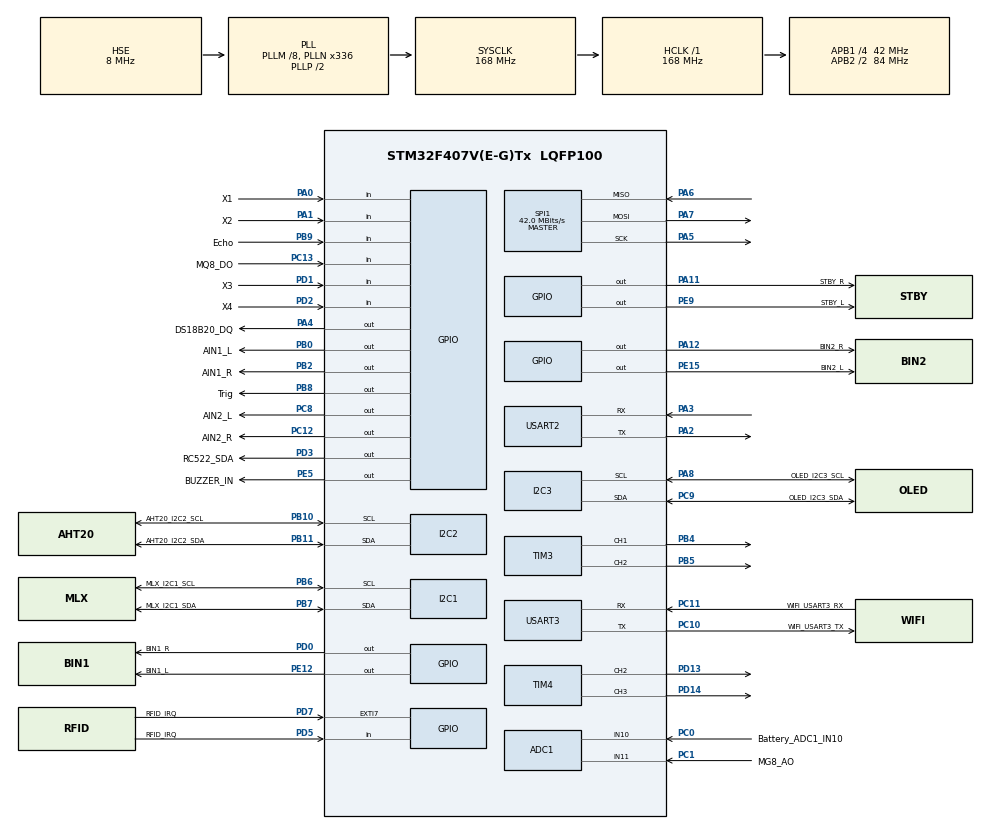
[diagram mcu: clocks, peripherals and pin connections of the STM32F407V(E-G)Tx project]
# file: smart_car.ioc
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ADC1.Channel-0\#ChannelRegularConversion=ADC_CHANNEL_10
ADC1.NbrOfConversionFlag=1
ADC1.Rank-0\#ChannelRegularConversion=1
ADC1.SamplingTime-0\#ChannelRegularConversion=ADC_SAMPLETIME_3CYCLES
ADC1.master=1
FREERTOS.Mutexes01=I2CMutex,Dynamic,NULL,Available
FREERTOS.Queues01=LEDFlash,16,uint32_t,0,Dynamic,NULL,NULL;Distance,16,float,0,Dynamic,NULL,NULL;Track,16,uint8_t,0,Dynamic,NULL,NULL;DriverPWM,16,uint32_t,0,Dynamic,NULL,NULL;MotorAction,16,12,1,Dynamic,NULL,NULL
FREERTOS.Tasks01=LedTask,8,256,StartLedTask,As weak,NULL,Dynamic,NULL,NULL;UartTask,8,256,StartUartTask,As external,NULL,Dynamic,NULL,NULL;OledTask,8,256,StartOledTask,As external,NULL,Dynamic,NULL,NULL;HCSR04Task,48,256,StartHCSR04Task,As external,NULL,Dynamic,NULL,NULL;SensorTask,17,256,StartSensorTask,As external,NULL,Dynamic,NULL,NULL;DriverTask,32,256,StartDriverTask,As external,NULL,Dynamic,NULL,NULL;CtrlTask,24,512,StartCtrlTask,As external,NULL,Dynamic,NULL,NULL;myRfidTask,8,256,StartRfidTask,As external,NULL,Dynamic,NULL,NULL;WifiTask,8,512,StartWifiTask,As external,NULL,Dynamic,NULL,NULL;AITask,8,512,StartAITask,As external,NULL,Dynamic,NULL,NULL
FREERTOS.configCHECK_FOR_STACK_OVERFLOW=2
FREERTOS.configTOTAL_HEAP_SIZE=24576
I2C3.I2C_Mode=I2C_Fast
Mcu.Family=STM32F4
Mcu.Name=STM32F407V(E-G)Tx
Mcu.Package=LQFP100
NVIC.PriorityGroup=NVIC_PRIORITYGROUP_4
NVIC.TIM1_CC_IRQn=true\:5\:0\:false\:false\:true\:true\:true\:true\:true
NVIC.TIM3_IRQn=true\:5\:0\:false\:false\:true\:false\:false\:true\:true
NVIC.TimeBase=TIM3_IRQn
NVIC.TimeBaseIP=TIM3
PA0-WKUP.GPIO_Label=X1
PA0-WKUP.GPIO_PuPd=GPIO_PULLUP
PA0-WKUP.Signal=GPIO_Input
PA1.GPIO_Label=X2
PA1.GPIO_PuPd=GPIO_PULLUP
PA1.Signal=GPIO_Input
PA11.GPIO_Label=STBY_R
PA11.PinState=GPIO_PIN_SET
PA11.Signal=GPIO_Output
PA12.GPIO_Label=BIN2_R
PA12.Signal=GPIO_Output
PA13.Mode=Serial_Wire
PA13.Signal=SYS_JTMS-SWDIO
PA14.Mode=Serial_Wire
PA14.Signal=SYS_JTCK-SWCLK
PA2.Mode=Asynchronous
PA2.Signal=USART2_TX
PA3.Mode=Asynchronous
PA3.Signal=USART2_RX
PA4.GPIO_Label=DS18B20_DQ
PA4.GPIO_ModeDefaultOutputPP=GPIO_MODE_OUTPUT_OD
PA4.GPIO_PuPd=GPIO_NOPULL
PA4.Signal=GPIO_Output
PA5.Mode=Full_Duplex_Master
PA5.Signal=SPI1_SCK
PA6.Mode=Full_Duplex_Master
PA6.Signal=SPI1_MISO
PA7.Mode=Full_Duplex_Master
PA7.Signal=SPI1_MOSI
PA8.GPIO_Label=OLED_I2C3_SCL
PA8.Mode=I2C
PA8.Signal=I2C3_SCL
PB0.GPIO_Label=AIN1_L
PB0.Signal=GPIO_Output
PB10.GPIO_Label=AHT20_I2C2_SCL
PB10.Mode=I2C
PB10.Signal=I2C2_SCL
PB11.GPIO_Label=AHT20_I2C2_SDA
PB11.Mode=I2C
PB11.Signal=I2C2_SDA
PB2.GPIO_Label=AIN1_R
PB2.Signal=GPIO_Output
PB4.Signal=S_TIM3_CH1
PB5.Signal=S_TIM3_CH2
PB6.GPIO_Label=MLX_I2C1_SCL
PB6.Mode=I2C
PB6.Signal=I2C1_SCL
PB7.GPIO_Label=MLX_I2C1_SDA
PB7.Mode=I2C
PB7.Signal=I2C1_SDA
PB8.GPIO_Label=Trig
PB8.Signal=GPIO_Output
PB9.GPIO_Label=Echo
PB9.Signal=GPIO_Input
PC0.GPIO_Label=Battery_ADC1_IN10
PC0.Signal=ADCx_IN10
PC1.GPIO_Label=MG8_AO
PC1.Signal=ADCx_IN11
PC10.GPIO_Label=WiFi_USART3_TX
PC10.Mode=Asynchronous
PC10.Signal=USART3_TX
PC11.GPIO_Label=WiFi_USART3_RX
PC11.Mode=Asynchronous
PC11.Signal=USART3_RX
PC12.GPIO_Label=AIN2_R
PC12.Signal=GPIO_Output
PC13-ANTI_TAMP.GPIO_Label=MQ8_DO
PC13-ANTI_TAMP.Signal=GPIO_Input
PC8.GPIO_Label=AIN2_L
PC8.Signal=GPIO_Output
PC9.GPIO_Label=OLED_I2C3_SDA
PC9.Mode=I2C
PC9.Signal=I2C3_SDA
PD0.GPIO_Label=BIN1_R
PD0.Signal=GPIO_Output
PD1.GPIO_Label=X3
PD1.GPIO_PuPd=GPIO_PULLUP
PD1.Signal=GPIO_Input
PD13.Signal=S_TIM4_CH2
PD14.Signal=S_TIM4_CH3
PD2.GPIO_Label=X4
PD2.GPIO_PuPd=GPIO_PULLUP
PD2.Signal=GPIO_Input
PD3.GPIO_Label=RC522_SDA
PD3.PinState=GPIO_PIN_SET
PD3.Signal=GPIO_Output
PD5.GPIO_Label=RFID_IRQ
PD5.Signal=GPIO_Input
PD7.GPIO_Label=RFID_IRQ 
PD7.Signal=GPXTI7
PE12.GPIO_Label=BIN1_L
PE12.Signal=GPIO_Output
PE15.GPIO_Label=BIN2_L
PE15.Signal=GPIO_Output
PE5.GPIO_Label=BUZZER_IN
PE5.PinState=GPIO_PIN_SET
PE5.Signal=GPIO_Output
PE9.GPIO_Label=STBY_L
PE9.PinState=GPIO_PIN_SET
PE9.Signal=GPIO_Output
PH0-OSC_IN.Mode=HSE-External-Oscillator
PH0-OSC_IN.Signal=RCC_OSC_IN
PH1-OSC_OUT.Mode=HSE-External-Oscillator
PH1-OSC_OUT.Signal=RCC_OSC_OUT
ProjectManager.HeapSize=0x200
ProjectManager.StackSize=0x400
ProjectManager.TargetToolchain=CMake
RCC.48MHZClocksFreq_Value=84000000
RCC.AHBFreq_Value=168000000
RCC.APB1CLKDivider=RCC_HCLK_DIV4
RCC.APB1Freq_Value=42000000
RCC.APB1TimFreq_Value=84000000
RCC.APB2CLKDivider=RCC_HCLK_DIV2
RCC.APB2Freq_Value=84000000
RCC.APB2TimFreq_Value=168000000
RCC.CortexFreq_Value=168000000
RCC.HCLKFreq_Value=168000000
RCC.HSE_VALUE=8000000
RCC.HSI_VALUE=16000000
RCC.LSE_VALUE=32768
RCC.PLLM=8
RCC.PLLN=336
RCC.PLLSourceVirtual=RCC_PLLSOURCE_HSE
RCC.SYSCLKFreq_VALUE=168000000
RCC.SYSCLKSource=RCC_SYSCLKSOURCE_PLLCLK
RCC.VCOOutputFreq_Value=336000000
SH.ADCx_IN10.0=ADC1_IN10,IN10
SH.ADCx_IN11.0=ADC1_IN11,IN11
SH.S_TIM3_CH1.0=TIM3_CH1,PWM Generation1 CH1
SH.S_TIM3_CH2.0=TIM3_CH2,PWM Generation2 CH2
SH.S_TIM4_CH2.0=TIM4_CH2,PWM Generation2 CH2
SH.S_TIM4_CH3.0=TIM4_CH3,PWM Generation3 CH3
SPI1.BaudRatePrescaler=SPI_BAUDRATEPRESCALER_2
SPI1.CalculateBaudRate=42.0 MBits/s
SPI1.Direction=SPI_DIRECTION_2LINES
SPI1.Mode=SPI_MODE_MASTER
SPI1.VirtualType=VM_MASTER
TIM1.Prescaler=167
TIM3.Channel-PWM\ Generation1\ CH1=TIM_CHANNEL_1
TIM3.Channel-PWM\ Generation2\ CH2=TIM_CHANNEL_2
TIM4.Channel-PWM\ Generation2\ CH2=TIM_CHANNEL_2
TIM4.Channel-PWM\ Generation3\ CH3=TIM_CHANNEL_3
USART2.VirtualMode=VM_ASYNC
USART3.VirtualMode=VM_ASYNC
VP_FREERTOS_VS_CMSIS_V2.Mode=CMSIS_V2
VP_SYS_VS_tim8.Mode=TIM8
VP_TIM1_VS_ClockSourceINT.Mode=Internal
board=custom

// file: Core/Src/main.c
/* USER CODE BEGIN Header */
/**
  ******************************************************************************
  * @file           : main.c
  * @brief          : Main program body
  ******************************************************************************
  * @attention
  *
  * Copyright (c) 2026 STMicroelectronics.
  * All rights reserved.
  *
  * This software is licensed under terms that can be found in the LICENSE file
  * in the root directory of this software component.
  * If no LICENSE file comes with this software, it is provided AS-IS.
  *
  ******************************************************************************
  */
/* USER CODE END Header */
#include "main.h"
#include "cmsis_os.h"
#include "adc.h"
#include "i2c.h"
#include "spi.h"
#include "tim.h"
#include "usart.h"
#include "gpio.h"

/* USER CODE BEGIN Includes */
#include "SelfTest.h"

/* USER CODE END Includes */

void SystemClock_Config(void);
void MX_FREERTOS_Init(void);

int main(void)
{

  /* MCU Configuration--------------------------------------------------------*/

  /* Reset of all peripherals, Initializes the Flash interface and the Systick. */
  HAL_Init();

  /* Configure the system clock */
  SystemClock_Config();

  /* Initialize all configured peripherals */
  MX_GPIO_Init();
  MX_I2C1_Init();
  MX_I2C2_Init();
  MX_I2C3_Init();
  MX_TIM4_Init();
  MX_USART2_UART_Init();
  MX_USART3_UART_Init();
  MX_ADC1_Init();
  MX_TIM1_Init();
  MX_SPI1_Init();
  MX_TIM3_Init();
  /* USER CODE BEGIN 2 */
  HAL_Delay(10U);
  SelfTest_Run();
  /* USER CODE END 2 */

  /* Init scheduler */
  osKernelInitialize();  /* Call init function for freertos objects (in cmsis_os2.c) */
  MX_FREERTOS_Init();

  /* Start scheduler */
  osKernelStart();

  /* We should never get here as control is now taken by the scheduler */

  /* Infinite loop */
  while (1)
  {

  }
}

void SystemClock_Config(void)
{
  RCC_OscInitTypeDef RCC_OscInitStruct = {0};
  RCC_ClkInitTypeDef RCC_ClkInitStruct = {0};

  /** Configure the main internal regulator output voltage
  */
  __HAL_RCC_PWR_CLK_ENABLE();
  __HAL_PWR_VOLTAGESCALING_CONFIG(PWR_REGULATOR_VOLTAGE_SCALE1);

  /** Initializes the RCC Oscillators according to the specified parameters
  * in the RCC_OscInitTypeDef structure.
  */
  RCC_OscInitStruct.OscillatorType = RCC_OSCILLATORTYPE_HSE;
  RCC_OscInitStruct.HSEState = RCC_HSE_ON;
  RCC_OscInitStruct.PLL.PLLState = RCC_PLL_ON;
  RCC_OscInitStruct.PLL.PLLSource = RCC_PLLSOURCE_HSE;
  RCC_OscInitStruct.PLL.PLLM = 8;
  RCC_OscInitStruct.PLL.PLLN = 336;
  RCC_OscInitStruct.PLL.PLLP = RCC_PLLP_DIV2;
  RCC_OscInitStruct.PLL.PLLQ = 4;
  if (HAL_RCC_OscConfig(&RCC_OscInitStruct) != HAL_OK)
  {
    Error_Handler();
  }

  /** Initializes the CPU, AHB and APB buses clocks
  */
  RCC_ClkInitStruct.ClockType = RCC_CLOCKTYPE_HCLK|RCC_CLOCKTYPE_SYSCLK
                              |RCC_CLOCKTYPE_PCLK1|RCC_CLOCKTYPE_PCLK2;
  RCC_ClkInitStruct.SYSCLKSource = RCC_SYSCLKSOURCE_PLLCLK;
  RCC_ClkInitStruct.AHBCLKDivider = RCC_SYSCLK_DIV1;
  RCC_ClkInitStruct.APB1CLKDivider = RCC_HCLK_DIV4;
  RCC_ClkInitStruct.APB2CLKDivider = RCC_HCLK_DIV2;

  if (HAL_RCC_ClockConfig(&RCC_ClkInitStruct, FLASH_LATENCY_5) != HAL_OK)
  {
    Error_Handler();
  }
}

void HAL_TIM_PeriodElapsedCallback(TIM_HandleTypeDef *htim)
{
  if (htim->Instance == TIM8)
  {
    HAL_IncTick();
  }
}

void Error_Handler(void)
{
  __disable_irq();
  while (1)
  {
  }
}

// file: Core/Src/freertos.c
/* USER CODE BEGIN Header */
/**
  ******************************************************************************
  * File Name          : freertos.c
  * Description        : Code for freertos applications
  ******************************************************************************
  * @attention
  *
  * Copyright (c) 2026 STMicroelectronics.
  * All rights reserved.
  *
  * This software is licensed under terms that can be found in the LICENSE file
  * in the root directory of this software component.
  * If no LICENSE file comes with this software, it is provided AS-IS.
  *
  ******************************************************************************
  */
/* USER CODE END Header */

#include "FreeRTOS.h"
#include "task.h"
#include "main.h"
#include "cmsis_os.h"

/* USER CODE BEGIN Includes */
#include "Ctrl.h"
#include "runtime_diag.h"

/* USER CODE END Includes */

/* USER CODE BEGIN Variables */
volatile uint32_t task_run_count[10] = {0};

/* USER CODE END Variables */
/* Definitions for LedTask */
osThreadId_t LedTaskHandle;
const osThreadAttr_t LedTask_attributes = {
  .name = "LedTask",
  .stack_size = 256 * 4,
  .priority = (osPriority_t) osPriorityLow,
};
/* Definitions for UartTask */
osThreadId_t UartTaskHandle;
const osThreadAttr_t UartTask_attributes = {
  .name = "UartTask",
  .stack_size = 256 * 4,
  .priority = (osPriority_t) osPriorityLow,
};
/* Definitions for OledTask */
osThreadId_t OledTaskHandle;
const osThreadAttr_t OledTask_attributes = {
  .name = "OledTask",
  .stack_size = 256 * 4,
  .priority = (osPriority_t) osPriorityLow,
};
/* Definitions for HCSR04Task */
osThreadId_t HCSR04TaskHandle;
const osThreadAttr_t HCSR04Task_attributes = {
  .name = "HCSR04Task",
  .stack_size = 256 * 4,
  .priority = (osPriority_t) osPriorityRealtime,
};
/* Definitions for SensorTask */
osThreadId_t SensorTaskHandle;
const osThreadAttr_t SensorTask_attributes = {
  .name = "SensorTask",
  .stack_size = 256 * 4,
  .priority = (osPriority_t) osPriorityBelowNormal1,
};
/* Definitions for DriverTask */
osThreadId_t DriverTaskHandle;
const osThreadAttr_t DriverTask_attributes = {
  .name = "DriverTask",
  .stack_size = 256 * 4,
  .priority = (osPriority_t) osPriorityAboveNormal,
};
/* Definitions for CtrlTask */
osThreadId_t CtrlTaskHandle;
const osThreadAttr_t CtrlTask_attributes = {
  .name = "CtrlTask",
  .stack_size = 512 * 4,
  .priority = (osPriority_t) osPriorityNormal,
};
/* Definitions for myRfidTask */
osThreadId_t myRfidTaskHandle;
const osThreadAttr_t myRfidTask_attributes = {
  .name = "myRfidTask",
  .stack_size = 256 * 4,
  .priority = (osPriority_t) osPriorityLow,
};
/* Definitions for WifiTask */
osThreadId_t WifiTaskHandle;
const osThreadAttr_t WifiTask_attributes = {
  .name = "WifiTask",
  .stack_size = 512 * 4,
  .priority = (osPriority_t) osPriorityLow,
};
/* Definitions for AITask */
osThreadId_t AITaskHandle;
const osThreadAttr_t AITask_attributes = {
  .name = "AITask",
  .stack_size = 512 * 4,
  .priority = (osPriority_t) osPriorityLow,
};
/* Definitions for LEDFlash */
osMessageQueueId_t LEDFlashHandle;
const osMessageQueueAttr_t LEDFlash_attributes = {
  .name = "LEDFlash"
};
/* Definitions for Distance */
osMessageQueueId_t DistanceHandle;
const osMessageQueueAttr_t Distance_attributes = {
  .name = "Distance"
};
/* Definitions for Track */
osMessageQueueId_t TrackHandle;
const osMessageQueueAttr_t Track_attributes = {
  .name = "Track"
};
/* Definitions for DriverPWM */
osMessageQueueId_t DriverPWMHandle;
const osMessageQueueAttr_t DriverPWM_attributes = {
  .name = "DriverPWM"
};
/* Definitions for MotorAction */
osMessageQueueId_t MotorActionHandle;
const osMessageQueueAttr_t MotorAction_attributes = {
  .name = "MotorAction"
};
/* Definitions for I2CMutex */
osMutexId_t I2CMutexHandle;
const osMutexAttr_t I2CMutex_attributes = {
  .name = "I2CMutex"
};

void StartLedTask(void *argument);
extern void StartUartTask(void *argument);
extern void StartOledTask(void *argument);
extern void StartHCSR04Task(void *argument);
extern void StartSensorTask(void *argument);
extern void StartDriverTask(void *argument);
extern void StartCtrlTask(void *argument);
extern void StartRfidTask(void *argument);
extern void StartWifiTask(void *argument);
extern void StartAITask(void *argument);

void MX_FREERTOS_Init(void); /* (MISRA C 2004 rule 8.1) */

/* Hook prototypes */
void vApplicationStackOverflowHook(xTaskHandle xTask, signed char *pcTaskName);

/* USER CODE BEGIN 4 */
void vApplicationStackOverflowHook(xTaskHandle xTask, signed char *pcTaskName)
{
   /* Run time stack overflow checking is performed if
   configCHECK_FOR_STACK_OVERFLOW is defined to 1 or 2. This hook function is
   called if a stack overflow is detected. */
   (void)xTask;
   RuntimeDiag_OnStackOverflow((const char *)pcTaskName);
}
/* USER CODE END 4 */

void MX_FREERTOS_Init(void) {
  /* Create the mutex(es) */
  /* creation of I2CMutex */
  I2CMutexHandle = osMutexNew(&I2CMutex_attributes);

  /* Create the queue(s) */
  /* creation of LEDFlash */
  LEDFlashHandle = osMessageQueueNew (16, sizeof(uint32_t), &LEDFlash_attributes);

  /* creation of Distance */
  DistanceHandle = osMessageQueueNew (16, sizeof(float), &Distance_attributes);

  /* creation of Track */
  TrackHandle = osMessageQueueNew (16, sizeof(uint8_t), &Track_attributes);

  /* creation of DriverPWM */
  DriverPWMHandle = osMessageQueueNew (16, sizeof(uint32_t), &DriverPWM_attributes);

  /* creation of MotorAction */
  MotorActionHandle = osMessageQueueNew (16, sizeof(MotorCmd_t), &MotorAction_attributes);

  /* USER CODE BEGIN RTOS_QUEUES */
  if (MotorActionHandle == NULL) {
    RuntimeDiag_AssertFailed(__FILE__, __LINE__);
  }
  /* USER CODE END RTOS_QUEUES */

  /* Create the thread(s) */
  /* creation of LedTask */
  LedTaskHandle = osThreadNew(StartLedTask, NULL, &LedTask_attributes);

  /* creation of UartTask */
  UartTaskHandle = osThreadNew(StartUartTask, NULL, &UartTask_attributes);

  /* creation of OledTask */
  OledTaskHandle = osThreadNew(StartOledTask, NULL, &OledTask_attributes);

  /* creation of HCSR04Task */
  HCSR04TaskHandle = osThreadNew(StartHCSR04Task, NULL, &HCSR04Task_attributes);

  /* creation of SensorTask */
  SensorTaskHandle = osThreadNew(StartSensorTask, NULL, &SensorTask_attributes);

  /* creation of DriverTask */
  DriverTaskHandle = osThreadNew(StartDriverTask, NULL, &DriverTask_attributes);

  /* creation of CtrlTask */
  CtrlTaskHandle = osThreadNew(StartCtrlTask, NULL, &CtrlTask_attributes);

  /* creation of myRfidTask */
  myRfidTaskHandle = osThreadNew(StartRfidTask, NULL, &myRfidTask_attributes);

  /* creation of WifiTask */
  WifiTaskHandle = osThreadNew(StartWifiTask, NULL, &WifiTask_attributes);

  /* creation of AITask */
  AITaskHandle = osThreadNew(StartAITask, NULL, &AITask_attributes);

}

__weak void StartLedTask(void *argument)
{
  for(;;)
  {
    osDelay(1);
  }
}
